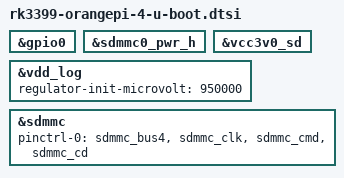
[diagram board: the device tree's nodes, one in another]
// SPDX-License-Identifier: GPL-2.0+

#include "rk3399-u-boot.dtsi"

&gpio0 {
	bootph-pre-ram;
};

&sdmmc0_pwr_h {
	bootph-pre-ram;
};

&vcc3v0_sd {
	bootph-pre-ram;
};

&vdd_log {
	regulator-init-microvolt = <950000>;
};

/*
 * U-Boot dw_mmc reads card detect from the controller, not cd-gpios.
 * Mux the pin to sdmmc_cd, else U-Boot sees no card.
 */
&sdmmc {
	pinctrl-0 = <&sdmmc_bus4 &sdmmc_clk &sdmmc_cmd &sdmmc_cd>;
};
